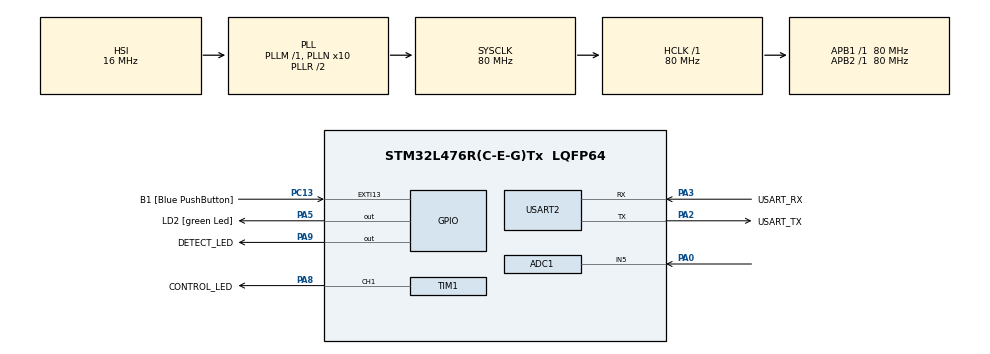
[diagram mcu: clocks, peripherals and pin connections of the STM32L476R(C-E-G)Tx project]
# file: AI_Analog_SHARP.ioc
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Mcu.Family=STM32L4
PA2.GPIO_PuPd=GPIO_NOPULL
STMicroelectronics.X-CUBE-AI.7.0.0.XAaCUBEAaAICcArtificialOoIntelligenceJjCore=true
RCC.CortexFreq_Value=80000000
ADC1.ContinuousConvMode=DISABLE
PH0-OSC_IN\ (PH0).Signal=RCC_OSC_IN
PA3.GPIO_PuPd=GPIO_NOPULL
PA2.GPIO_Speed=GPIO_SPEED_FREQ_VERY_HIGH
PC15-OSC32_OUT\ (PC15).Mode=LSE-External-Oscillator
PC13.GPIO_Label=B1 [Blue PushButton]
PA3.GPIO_Speed=GPIO_SPEED_FREQ_VERY_HIGH
RCC.SYSCLKSource=RCC_SYSCLKSOURCE_PLLCLK
ProjectManager.StackSize=0x800
PB3\ (JTDO-TRACESWO).Signal=SYS_JTDO-SWO
PC14-OSC32_IN\ (PC14).Mode=LSE-External-Oscillator
STMicroelectronics.X-CUBE-AI.7.0.0.ActivationBufferSizeList=388
PA14\ (JTCK-SWCLK).Signal=SYS_JTCK-SWCLK
TIM1.Prescaler=8000-1
RCC.HCLKFreq_Value=80000000
RCC.APB2TimFreq_Value=80000000
TIM3.Period=400-1
Dma.ADC1.0.Direction=DMA_PERIPH_TO_MEMORY
STMicroelectronics.X-CUBE-AI.7.0.0.ModelStructureFile-90d25b0485dd15f15ca06fa10e7a8d1330ec9c54936d5b2f049c2284db77fe1c=C\:\\Users\\piotr\\Desktop\\data_AI_1_2.h5
Dma.ADC1.0.MemDataAlignment=DMA_MDATAALIGN_HALFWORD
RCC.AHBFreq_Value=80000000
RCC.PREFETCH_ENABLE=1
STMicroelectronics.X-CUBE-AI.7.0.0.MaximumSizeOfOutputLayer=AI_NETWORK_OUT_1_SIZE_BYTES
STMicroelectronics.X-CUBE-AI.7.0.0.ModelName-90d25b0485dd15f15ca06fa10e7a8d1330ec9c54936d5b2f049c2284db77fe1c=network
NVIC.EXTI15_10_IRQn=true\:0\:0\:false\:false\:true\:true\:true
RCC.HSE_VALUE=8000000
STMicroelectronics.X-CUBE-AI.7.0.0.MaximumNumberOfOutputLayer=1
USART2.VirtualMode-Asynchronous=VM_ASYNC
STMicroelectronics.X-CUBE-AI.7.0.0.ModelNameList=network
TIM1.Channel-PWM\ Generation1\ CH1=TIM_CHANNEL_1
STMicroelectronics.X-CUBE-AI.7.0.0.HeapSize=0x800
TIM3.Prescaler=8000-1
Dma.ADC1.0.PeriphInc=DMA_PINC_DISABLE
PA5.GPIO_PuPd=GPIO_NOPULL
PC13.GPIO_PuPd=GPIO_NOPULL
STMicroelectronics.X-CUBE-AI.7.0.0.StackSize=0x800
PA8.Signal=S_TIM1_CH1
PA0.Signal=ADCx_IN5
Mcu.Package=LQFP64
PA2.GPIO_Label=USART_TX
ADC1.OffsetNumber-1\#ChannelRegularConversion=ADC_OFFSET_NONE
RCC.APB1TimFreq_Value=80000000
STMicroelectronics.X-CUBE-AI.7.0.0.ModelMacc-90d25b0485dd15f15ca06fa10e7a8d1330ec9c54936d5b2f049c2284db77fe1c=1371
TIM1.Period=100-1
PA13\ (JTMS-SWDIO).Signal=SYS_JTMS-SWDIO
Dma.Request0=ADC1
VP_TIM3_VS_ClockSourceINT.Mode=Internal
STMicroelectronics.X-CUBE-AI.7.0.0.ModelHashList=90d25b0485dd15f15ca06fa10e7a8d1330ec9c54936d5b2f049c2284db77fe1c
PA3.Signal=USART2_RX
PA2.GPIO_Mode=GPIO_MODE_AF_PP
RCC.MSI_VALUE=4000000
RCC.PLLSourceVirtual=RCC_PLLSOURCE_HSI
PA14\ (JTCK-SWCLK).Mode=Serial_Wire
Dma.ADC1.0.Instance=DMA1_Channel1
STMicroelectronics.X-CUBE-AI.7.0.0.ModelKind-90d25b0485dd15f15ca06fa10e7a8d1330ec9c54936d5b2f049c2284db77fe1c=KERAS
STMicroelectronics.X-CUBE-AI.7.0.0.MaximumNumberOfInputLayer=1
STMicroelectronics.X-CUBE-AI.7.0.0.WorkingBufferStartAddrList=0xFFFFFFFF
STMicroelectronics.X-CUBE-AI.7.0.0.InternalRamActivationBufferMaxSize=AI_NETWORK_DATA_ACTIVATIONS_SIZE
STMicroelectronics.X-CUBE-AI.7.0.0.ReadyForCodeGeneration=true
PC13.Signal=GPXTI13
PA9.GPIO_Label=DETECT_LED
PC15-OSC32_OUT\ (PC15).Signal=RCC_OSC32_OUT
PA14\ (JTCK-SWCLK).GPIO_Label=TCK
PB3\ (JTDO-TRACESWO).GPIO_Label=SWO
VP_STMicroelectronics.X-CUBE-AI_VS_DeviceJjApplication_7.0.0.Mode=DeviceJjApplication
STMicroelectronics.X-CUBE-AI.7.0.0.ModelFlashOccupation-90d25b0485dd15f15ca06fa10e7a8d1330ec9c54936d5b2f049c2284db77fe1c=5316
PH1-OSC_OUT\ (PH1).Signal=RCC_OSC_OUT
STMicroelectronics.X-CUBE-AI.7.0.0.ModelCompression-90d25b0485dd15f15ca06fa10e7a8d1330ec9c54936d5b2f049c2284db77fe1c=1
PA3.Mode=Asynchronous
Dma.ADC1.0.PeriphDataAlignment=DMA_PDATAALIGN_HALFWORD
PA8.GPIO_Label=CONTROL_LED
SH.S_TIM1_CH1.0=TIM1_CH1,PWM Generation1 CH1
ProjectManager.TargetToolchain=STM32CubeIDE
Dma.ADC1.0.Mode=DMA_CIRCULAR
PA3.GPIO_Mode=GPIO_MODE_AF_PP
Dma.ADC1.0.Priority=DMA_PRIORITY_LOW
PA9.Signal=GPIO_Output
ADC1.Channel-1\#ChannelRegularConversion=ADC_CHANNEL_5
STMicroelectronics.X-CUBE-AI.7.0.0.MaximumSizeOfInputLayer=AI_NETWORK_IN_1_SIZE_BYTES
RCC.USBFreq_Value=64000000
STMicroelectronics.X-CUBE-AI.7.0.0.ModelRamOccupation-90d25b0485dd15f15ca06fa10e7a8d1330ec9c54936d5b2f049c2284db77fe1c=388
PA5.Signal=GPIO_Output
board=NUCLEO-L476RG
RCC.VCOOutputFreq_Value=160000000
RCC.APB2Freq_Value=80000000
PA5.GPIO_ModeDefaultOutputPP=GPIO_MODE_OUTPUT_PP
PA13\ (JTMS-SWDIO).GPIO_Label=TMS
RCC.ADCFreq_Value=64000000
STMicroelectronics.X-CUBE-AI.7.0.0.ModelType-90d25b0485dd15f15ca06fa10e7a8d1330ec9c54936d5b2f049c2284db77fe1c=Saved model
ADC1.DMAContinuousRequests=ENABLE
ADC1.NbrOfConversion=1
Mcu.Name=STM32L476R(C-E-G)Tx
PA2.Signal=USART2_TX
ADC1.ExternalTrigConv=ADC_EXTERNALTRIG_T3_TRGO
PA13\ (JTMS-SWDIO).Mode=Serial_Wire
ADC1.SamplingTime-1\#ChannelRegularConversion=ADC_SAMPLETIME_640CYCLES_5
RCC.SYSCLKFreq_VALUE=80000000
ADC1.master=1
STMicroelectronics.X-CUBE-AI.7.0.0.ApplicationCcDeviceJjApplication=ApplicationTemplate
PA5.GPIO_Label=LD2 [green Led]
PC13.GPIO_ModeDefaultEXTI=GPIO_MODE_IT_FALLING
PC14-OSC32_IN\ (PC14).Signal=RCC_OSC32_IN
ADC1.Rank-1\#ChannelRegularConversion=1
Dma.ADC1.0.MemInc=DMA_MINC_DISABLE
ProjectManager.HeapSize=0x800
VP_STMicroelectronics.X-CUBE-AI_VS_ArtificialOoIntelligenceJjXAaCUBEAaAI_7.0.0.Mode=ArtificialOoIntelligenceJjXAaCUBEAaAI
RCC.HSI_VALUE=16000000
SH.ADCx_IN5.0=ADC1_IN5,IN5-Single-Ended
PA5.GPIO_Speed=GPIO_SPEED_FREQ_LOW
NVIC.PriorityGroup=NVIC_PRIORITYGROUP_4
ADC1.NbrOfConversionFlag=1
RCC.PLLN=10
PA2.Mode=Asynchronous
NVIC.DMA1_Channel1_IRQn=true\:0\:0\:false\:false\:true\:false\:true
TIM3.TIM_MasterOutputTrigger=TIM_TRGO_UPDATE
STMicroelectronics.X-CUBE-AI.7.0.0.ModelActualCompression-90d25b0485dd15f15ca06fa10e7a8d1330ec9c54936d5b2f049c2284db77fe1c=0.0
RCC.APB1Freq_Value=80000000
VP_CRC_VS_CRC.Mode=CRC_Activate
STMicroelectronics.X-CUBE-AI.7.0.0.LatestDirectoryUsed-90d25b0485dd15f15ca06fa10e7a8d1330ec9c54936d5b2f049c2284db77fe1c=C\:\\Users\\piotr\\Desktop
PA3.GPIO_Label=USART_RX

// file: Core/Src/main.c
/* USER CODE BEGIN Header */
/**
  ******************************************************************************
  * @file           : main.c
  * @brief          : Main program body
  ******************************************************************************
  * @attention
  *
  * <h2><center>&copy; Copyright (c) 2021 STMicroelectronics.
  * All rights reserved.</center></h2>
  *
  * This software component is licensed by ST under BSD 3-Clause license,
  * the "License"; You may not use this file except in compliance with the
  * License. You may obtain a copy of the License at:
  *                        opensource.org/licenses/BSD-3-Clause
  *
  ******************************************************************************
  */
/* USER CODE END Header */
#include "main.h"
#include "adc.h"
#include "crc.h"
#include "dma.h"
#include "tim.h"
#include "usart.h"
#include "gpio.h"
#include "app_x-cube-ai.h"

/* USER CODE BEGIN Includes */
#include "ai_sharp_sensor.h"
/* USER CODE END Includes */

void SystemClock_Config(void);

int main(void)
{

  /* MCU Configuration--------------------------------------------------------*/

  /* Reset of all peripherals, Initializes the Flash interface and the Systick. */
  HAL_Init();

  /* Configure the system clock */
  SystemClock_Config();

  /* Initialize all configured peripherals */
  MX_GPIO_Init();
  MX_DMA_Init();
  MX_USART2_UART_Init();
  MX_ADC1_Init();
  MX_TIM3_Init();
  MX_CRC_Init();
  MX_TIM1_Init();
  MX_X_CUBE_AI_Init();
  /* USER CODE BEGIN 2 */
  ADC_start_data_measurement();
  HAL_TIM_PWM_Start(&htim1, TIM_CHANNEL_1);
  /* USER CODE END 2 */

  /* Infinite loop */
  /* USER CODE BEGIN WHILE */
  while (1)
  {
	  //ai_sharp_train_data_collect();
	  LED_brightness_control();
    /* USER CODE END WHILE */

  MX_X_CUBE_AI_Process();
  }
}

void SystemClock_Config(void)
{
  RCC_OscInitTypeDef RCC_OscInitStruct = {0};
  RCC_ClkInitTypeDef RCC_ClkInitStruct = {0};
  RCC_PeriphCLKInitTypeDef PeriphClkInit = {0};

  /** Initializes the RCC Oscillators according to the specified parameters
  * in the RCC_OscInitTypeDef structure.
  */
  RCC_OscInitStruct.OscillatorType = RCC_OSCILLATORTYPE_HSI;
  RCC_OscInitStruct.HSIState = RCC_HSI_ON;
  RCC_OscInitStruct.HSICalibrationValue = RCC_HSICALIBRATION_DEFAULT;
  RCC_OscInitStruct.PLL.PLLState = RCC_PLL_ON;
  RCC_OscInitStruct.PLL.PLLSource = RCC_PLLSOURCE_HSI;
  RCC_OscInitStruct.PLL.PLLM = 1;
  RCC_OscInitStruct.PLL.PLLN = 10;
  RCC_OscInitStruct.PLL.PLLP = RCC_PLLP_DIV7;
  RCC_OscInitStruct.PLL.PLLQ = RCC_PLLQ_DIV2;
  RCC_OscInitStruct.PLL.PLLR = RCC_PLLR_DIV2;
  if (HAL_RCC_OscConfig(&RCC_OscInitStruct) != HAL_OK)
  {
    Error_Handler();
  }
  /** Initializes the CPU, AHB and APB buses clocks
  */
  RCC_ClkInitStruct.ClockType = RCC_CLOCKTYPE_HCLK|RCC_CLOCKTYPE_SYSCLK
                              |RCC_CLOCKTYPE_PCLK1|RCC_CLOCKTYPE_PCLK2;
  RCC_ClkInitStruct.SYSCLKSource = RCC_SYSCLKSOURCE_PLLCLK;
  RCC_ClkInitStruct.AHBCLKDivider = RCC_SYSCLK_DIV1;
  RCC_ClkInitStruct.APB1CLKDivider = RCC_HCLK_DIV1;
  RCC_ClkInitStruct.APB2CLKDivider = RCC_HCLK_DIV1;

  if (HAL_RCC_ClockConfig(&RCC_ClkInitStruct, FLASH_LATENCY_4) != HAL_OK)
  {
    Error_Handler();
  }
  PeriphClkInit.PeriphClockSelection = RCC_PERIPHCLK_USART2|RCC_PERIPHCLK_ADC;
  PeriphClkInit.Usart2ClockSelection = RCC_USART2CLKSOURCE_PCLK1;
  PeriphClkInit.AdcClockSelection = RCC_ADCCLKSOURCE_PLLSAI1;
  PeriphClkInit.PLLSAI1.PLLSAI1Source = RCC_PLLSOURCE_HSI;
  PeriphClkInit.PLLSAI1.PLLSAI1M = 1;
  PeriphClkInit.PLLSAI1.PLLSAI1N = 8;
  PeriphClkInit.PLLSAI1.PLLSAI1P = RCC_PLLP_DIV7;
  PeriphClkInit.PLLSAI1.PLLSAI1Q = RCC_PLLQ_DIV2;
  PeriphClkInit.PLLSAI1.PLLSAI1R = RCC_PLLR_DIV2;
  PeriphClkInit.PLLSAI1.PLLSAI1ClockOut = RCC_PLLSAI1_ADC1CLK;
  if (HAL_RCCEx_PeriphCLKConfig(&PeriphClkInit) != HAL_OK)
  {
    Error_Handler();
  }
  /** Configure the main internal regulator output voltage
  */
  if (HAL_PWREx_ControlVoltageScaling(PWR_REGULATOR_VOLTAGE_SCALE1) != HAL_OK)
  {
    Error_Handler();
  }
}

void Error_Handler(void)
{
  __disable_irq();
  while (1)
  {
  }
}

/************************ (C) COPYRIGHT STMicroelectronics *****END OF FILE****/
